AUTOSAR XML (schema 00046)
package /ComponentTypes
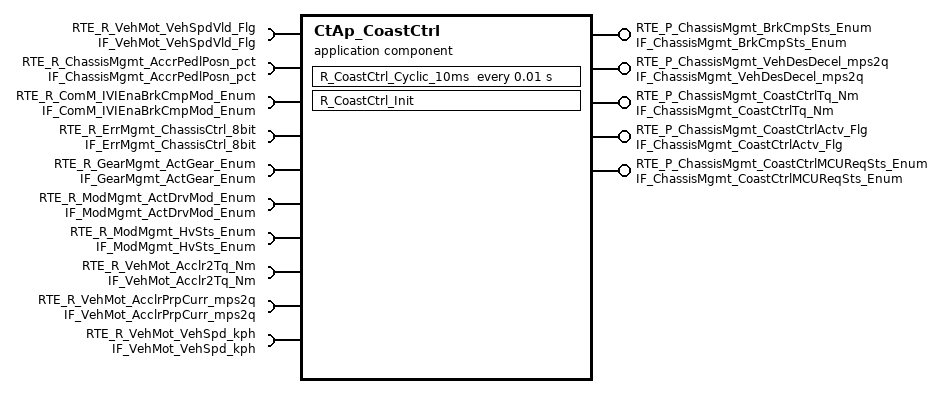
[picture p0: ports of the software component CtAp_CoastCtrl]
  application sw component type CtAp_CoastCtrl
    5 x provide port:
      RTE_P_ChassisMgmt_BrkCmpSts_Enum: nonqueued-sender-com-spec{data-element=tec_ChassisMgmt_BrkCmpSts_Enum, init-value=0}, provided-interface=IF_ChassisMgmt_BrkCmpSts_Enum
      RTE_P_ChassisMgmt_VehDesDecel_mps2q: nonqueued-sender-com-spec{data-element=tec_ChassisMgmt_BrkCmpDesDecel_mps2q, init-value=0}, provided-interface=IF_ChassisMgmt_VehDesDecel_mps2q
      RTE_P_ChassisMgmt_CoastCtrlTq_Nm: nonqueued-sender-com-spec{data-element=tec_ChassisMgmt_CoastCtrlTq_Nm, init-value=0}, provided-interface=IF_ChassisMgmt_CoastCtrlTq_Nm
      RTE_P_ChassisMgmt_CoastCtrlActv_Flg: nonqueued-sender-com-spec{data-element=tec_ChassisMgmt_CoastCtrlActv_Flg, init-value=0}, provided-interface=IF_ChassisMgmt_CoastCtrlActv_Flg
      RTE_P_ChassisMgmt_CoastCtrlMCUReqSts_Enum: nonqueued-sender-com-spec{data-element=tec_ChassisMgmt_CoastCtrlMCUReqSts_Enum, init-value=0}, provided-interface=IF_ChassisMgmt_CoastCtrlMCUReqSts_Enum
    10 x require port:
      RTE_R_VehMot_VehSpdVld_Flg: nonqueued-receiver-com-spec{data-element=tec_VehMot_VehSpdVld_Flg, filter=data-filter-type=ALWAYS, init-value=0}, required-interface=IF_VehMot_VehSpdVld_Flg
      RTE_R_ChassisMgmt_AccrPedlPosn_pct: nonqueued-receiver-com-spec{data-element=tec_ChassisMgmt_AccrPedlPosn_pct, filter=data-filter-type=ALWAYS, init-value=0}, required-interface=IF_ChassisMgmt_AccrPedlPosn_pct
      RTE_R_ComM_IVIEnaBrkCmpMod_Enum: nonqueued-receiver-com-spec{data-element=tec_ComM_IVIEnaBrkCmpMod_Enum, filter=data-filter-type=ALWAYS, init-value=0}, required-interface=IF_ComM_IVIEnaBrkCmpMod_Enum
      RTE_R_ErrMgmt_ChassisCtrl_8bit: nonqueued-receiver-com-spec{data-element=tec_ErrMgmt_ChassisCtrl_8bit, filter=data-filter-type=ALWAYS, init-value=0}, required-interface=IF_ErrMgmt_ChassisCtrl_8bit
      RTE_R_GearMgmt_ActGear_Enum: nonqueued-receiver-com-spec{data-element=tec_GearMgmt_ActGear_Enum, filter=data-filter-type=ALWAYS, init-value=0}, required-interface=IF_GearMgmt_ActGear_Enum
      RTE_R_ModMgmt_ActDrvMod_Enum: nonqueued-receiver-com-spec{data-element=tec_ModMgmt_ActDrvMod_Enum, filter=data-filter-type=ALWAYS, init-value=0}, required-interface=IF_ModMgmt_ActDrvMod_Enum
      RTE_R_ModMgmt_HvSts_Enum: nonqueued-receiver-com-spec{data-element=tec_ModMgmt_HvSts_Enum, filter=data-filter-type=ALWAYS, init-value=0}, required-interface=IF_ModMgmt_HvSts_Enum
      RTE_R_VehMot_Acclr2Tq_Nm: nonqueued-receiver-com-spec{data-element=tec_VehMot_Acclr2Tq_Nm, filter=data-filter-type=ALWAYS, init-value=0}, required-interface=IF_VehMot_Acclr2Tq_Nm
      RTE_R_VehMot_AcclrPrpCurr_mps2q: nonqueued-receiver-com-spec{data-element=tec_VehMot_AcclrPrpCurr_mps2q, filter=data-filter-type=ALWAYS, init-value=0}, required-interface=IF_VehMot_AcclrPrpCurr_mps2q
      RTE_R_VehMot_VehSpd_kph: nonqueued-receiver-com-spec{data-element=tec_VehMot_VehSpd_kph, filter=data-filter-type=ALWAYS, init-value=0}, required-interface=IF_VehMot_VehSpd_kph
    behavior CtAp_CoastCtrl_InternalBehavior
      init event CtAp_CoastCtrl_InitEvent: start-on-event=R_CoastCtrl_Init
      timing event TMT_R_CoastCtrl_Cyclic_10ms: start-on-event=R_CoastCtrl_Cyclic_10ms, period=0.01
      runnable R_CoastCtrl_Init
      runnable R_CoastCtrl_Cyclic_10ms
        data-receive-point-by-arguments:
          10 x access:
            REC_RTE_R_ChassisMgmt_AccrPedlPosn_pct_tec_ChassisMgmt_AccrPedlPosn_pct: accessed-variable=RTE_R_ChassisMgmt_AccrPedlPosn_pct.tec_ChassisMgmt_AccrPedlPosn_pct
            REC_RTE_R_ComM_IVIEnaBrkCmpMod_Enum_tec_ComM_IVIEnaBrkCmpMod_Enum: accessed-variable=RTE_R_ComM_IVIEnaBrkCmpMod_Enum.tec_ComM_IVIEnaBrkCmpMod_Enum
            REC_RTE_R_ErrMgmt_ChassisCtrl_8bit_tec_ErrMgmt_ChassisCtrl_8bit: accessed-variable=RTE_R_ErrMgmt_ChassisCtrl_8bit.tec_ErrMgmt_ChassisCtrl_8bit
            REC_RTE_R_GearMgmt_ActGear_Enum_tec_GearMgmt_ActGear_Enum: accessed-variable=RTE_R_GearMgmt_ActGear_Enum.tec_GearMgmt_ActGear_Enum
            REC_RTE_R_ModMgmt_ActDrvMod_Enum_tec_ModMgmt_ActDrvMod_Enum: accessed-variable=RTE_R_ModMgmt_ActDrvMod_Enum.tec_ModMgmt_ActDrvMod_Enum
            REC_RTE_R_ModMgmt_HvSts_Enum_tec_ModMgmt_HvSts_Enum: accessed-variable=RTE_R_ModMgmt_HvSts_Enum.tec_ModMgmt_HvSts_Enum
            REC_RTE_R_VehMot_Acclr2Tq_Nm_tec_VehMot_Acclr2Tq_Nm: accessed-variable=RTE_R_VehMot_Acclr2Tq_Nm.tec_VehMot_Acclr2Tq_Nm
            REC_RTE_R_VehMot_AcclrPrpCurr_mps2q_tec_VehMot_AcclrPrpCurr_mps2q: accessed-variable=RTE_R_VehMot_AcclrPrpCurr_mps2q.tec_VehMot_AcclrPrpCurr_mps2q
            REC_RTE_R_VehMot_VehSpdVld_Flg_tec_VehMot_VehSpdVld_Flg: accessed-variable=RTE_R_VehMot_VehSpdVld_Flg.tec_VehMot_VehSpdVld_Flg
            REC_RTE_R_VehMot_VehSpd_kph_tec_VehMot_VehSpd_kph: accessed-variable=RTE_R_VehMot_VehSpd_kph.tec_VehMot_VehSpd_kph
        data-send-points:
          5 x access:
            SEND_RTE_P_ChassisMgmt_BrkCmpSts_Enum_tec_ChassisMgmt_BrkCmpSts_Enum: accessed-variable=RTE_P_ChassisMgmt_BrkCmpSts_Enum.tec_ChassisMgmt_BrkCmpSts_Enum
            SEND_RTE_P_ChassisMgmt_CoastCtrlActv_Flg_tec_ChassisMgmt_CoastCtrlActv_Flg: accessed-variable=RTE_P_ChassisMgmt_CoastCtrlActv_Flg.tec_ChassisMgmt_CoastCtrlActv_Flg
            SEND_RTE_P_ChassisMgmt_CoastCtrlMCUReqSts_Enum_tec_ChassisMgmt_CoastCtrlMCUReqSts_Enum: accessed-variable=RTE_P_ChassisMgmt_CoastCtrlMCUReqSts_Enum.tec_ChassisMgmt_CoastCtrlMCUReqSts_Enum
            SEND_RTE_P_ChassisMgmt_CoastCtrlTq_Nm_tec_ChassisMgmt_CoastCtrlTq_Nm: accessed-variable=RTE_P_ChassisMgmt_CoastCtrlTq_Nm.tec_ChassisMgmt_CoastCtrlTq_Nm
            SEND_RTE_P_ChassisMgmt_VehDesDecel_mps2q_tec_ChassisMgmt_BrkCmpDesDecel_mps2q: accessed-variable=RTE_P_ChassisMgmt_VehDesDecel_mps2q.tec_ChassisMgmt_BrkCmpDesDecel_mps2q
  swc implementation CtAp_CoastCtrl_Implementation: behavior=CtAp_CoastCtrl_InternalBehavior
    code-descriptors:
      code Default: artifact-descriptors=autosar-engineering-object=category=SWOBJ
